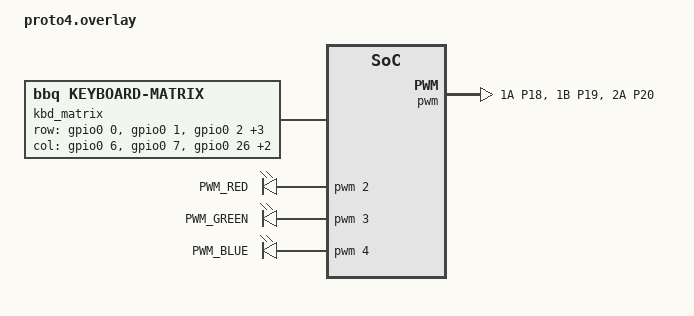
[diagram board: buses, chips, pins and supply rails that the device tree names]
/* Device tree overlay for Proto2 keyboard matrix
 *
 * This board only supports the sparkfun_promicro_rp2040 board, which is mounted
 * directly onto the board, so we don't use the connector, but just directly
 * attach to the GPIOs.
 */

#include <zephyr/dt-bindings/pwm/pwm.h>

/ {
	aliases {
		matrix = &kbd_matrix;
	};

	chosen {
		zephyr,matrix = &kbd_matrix;
		bbq,pwm-leds = &pwm_leds;
		// bbq,led-strip = &ws2812;
		bbq,two-row;
	};

	kbd_matrix: kbd-matrix {
		compatible = "bbq,keyboard-matrix";
		row-gpios = <&gpio0 0 (GPIO_PULL_DOWN | GPIO_ACTIVE_HIGH)>,
			    <&gpio0 1 (GPIO_PULL_DOWN | GPIO_ACTIVE_HIGH)>,
			    <&gpio0 2 (GPIO_PULL_DOWN | GPIO_ACTIVE_HIGH)>,
			    <&gpio0 3 (GPIO_PULL_DOWN | GPIO_ACTIVE_HIGH)>,
			    <&gpio0 4 (GPIO_PULL_DOWN | GPIO_ACTIVE_HIGH)>,
			    <&gpio0 5 (GPIO_PULL_DOWN | GPIO_ACTIVE_HIGH)>;
		col-gpios = <&gpio0 6 GPIO_ACTIVE_HIGH>,
			    <&gpio0 7 GPIO_ACTIVE_HIGH>,
			    <&gpio0 26 GPIO_ACTIVE_HIGH>,
			    <&gpio0 27 GPIO_ACTIVE_HIGH>,
			    <&gpio0 28 GPIO_ACTIVE_HIGH>;
                translate = "proto4";
                /* reverse-scan; */
		idle-mode = "scan";
	};

        /* No side select, as there is only one "side" as far as software is concerned.
        side_select {
                compatible = "bbq,gpio-mode-selector";
                in-gpios = <&gpio0 27 (GPIO_PULL_UP | GPIO_ACTIVE_HIGH)>;
        };
        */
};

&leds {
	status = "disabled";
};

&pinctrl {
	pwm_default: pwm_default {
		group1 {
			pinmux = <PWM_1A_P18>, <PWM_1B_P19>, <PWM_2A_P20>;
		};
	};
};

/ {
	pwm_leds: pwm_leds {
		compatible = "pwm-leds";
		status = "okay";

		pwm_red: pwm_led_0 {
			pwms = <&pwm 2 PWM_MSEC(20) PWM_POLARITY_INVERTED>;
			label = "PWM_RED";
		};

		pwm_green: pwm_led_1 {
			pwms = <&pwm 3 PWM_MSEC(20) PWM_POLARITY_INVERTED>;
			label = "PWM_GREEN";
		};

		pwm_blue: pwm_led_2 {
			pwms = <&pwm 4 PWM_MSEC(20) PWM_POLARITY_INVERTED>;
			label = "PWM_BLUE";
		};
	};
};

&pwm {
	status = "okay";
	pinctrl-0 = <&pwm_default>;
	pinctrl-names = "default";
	divider-int-0 = <255>;
	divider-int-1 = <255>;
	divider-int-2 = <255>;
	divider-frac-0 = <15>;
	divider-frac-1 = <15>;
	divider-frac-2 = <15>;
};
